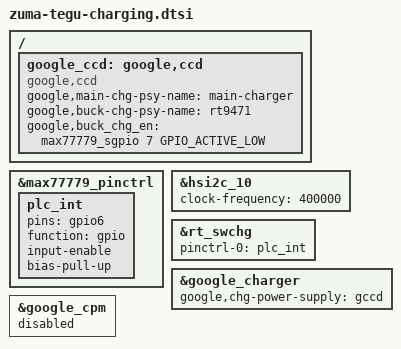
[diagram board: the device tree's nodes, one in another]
// SPDX-License-Identifier: GPL-2.0-only
/*
 * Charging device tree entries specific to Tegu devices
 *
 * Copyright 2023 Google LLC
 *
 */

/ {
	fragment@charging {
		target-path = "/";
		__overlay__ {

			google_ccd: google,ccd {
				status = "okay";
				compatible = "google,ccd";
				google,main-chg-psy-name = "main-charger";
				google,buck-chg-psy-name = "rt9471";

				google,buck_chg_en = <&max77779_sgpio 7 GPIO_ACTIVE_LOW>;
			};

		};
	};
};

&max77779_pinctrl {
	/* PLC_INT_L rt9470 Interrupt */
	plc_int: plc_int {
		pins = "gpio6";
		function = "gpio";
		input-enable;
		bias-pull-up;
	};
};

&hsi2c_10 {
	#address-cells = <1>;
	#size-cells = <0>;
	status = "okay";
	clock-frequency = <400000>;

	#include "zumapro-buck-charge-rt9471.dtsi"
};

&rt_swchg {
	pinctrl-names = "default";
	pinctrl-0 = <&plc_int>;
};

&google_charger {
	google,chg-power-supply = "gccd";
};

&google_cpm {
	status = "disabled";
};
